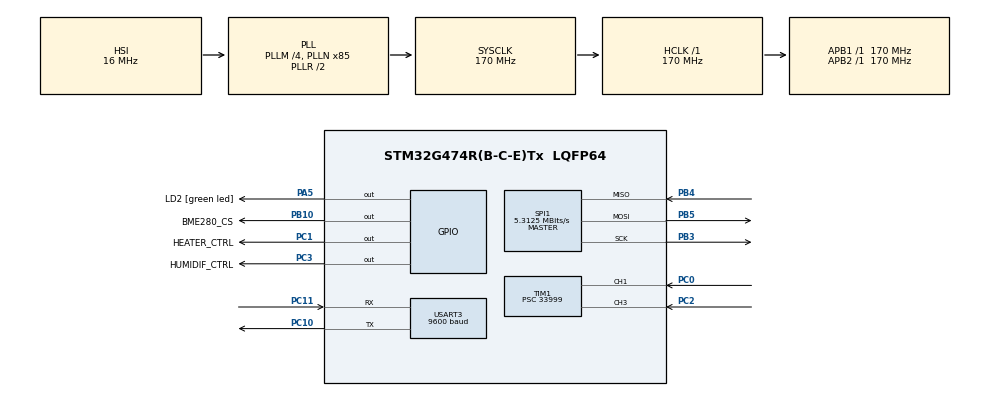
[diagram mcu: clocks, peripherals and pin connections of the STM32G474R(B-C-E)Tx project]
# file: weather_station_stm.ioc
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Mcu.Family=STM32G4
Mcu.Name=STM32G474R(B-C-E)Tx
Mcu.Package=LQFP64
NVIC.PriorityGroup=NVIC_PRIORITYGROUP_4
NVIC.SPI1_IRQn=true\:5\:0\:true\:false\:true\:true\:true\:true
NVIC.TIM1_CC_IRQn=true\:5\:0\:true\:false\:true\:true\:true\:true
NVIC.TIM1_UP_TIM16_IRQn=true\:5\:0\:true\:false\:true\:false\:true\:true
NVIC.TimeBase=TIM1_UP_TIM16_IRQn
NVIC.TimeBaseIP=TIM16
NVIC.USART3_IRQn=true\:5\:0\:true\:false\:true\:true\:true\:true
PA13.GPIO_Label=T_SWDIO
PA13.Mode=Serial_Wire
PA13.Signal=SYS_JTMS-SWDIO
PA14.GPIO_Label=T_SWCLK
PA14.Mode=Serial_Wire
PA14.Signal=SYS_JTCK-SWCLK
PA2.GPIO_Label=LPUART1_TX [STLINKV3E_VCP_RX]
PA2.Signal=LPUART1_TX
PA3.GPIO_Label=LPUART1_RX [STLINKV3E_VCP_TX]
PA3.Signal=LPUART1_RX
PA5.GPIO_Label=LD2 [green led]
PA5.Signal=GPIO_Output
PB10.GPIO_Label=BME280_CS
PB10.Signal=GPIO_Output
PB3.Mode=Full_Duplex_Master
PB3.Signal=SPI1_SCK
PB4.Mode=Full_Duplex_Master
PB4.Signal=SPI1_MISO
PB5.Mode=Full_Duplex_Master
PB5.Signal=SPI1_MOSI
PC0.Signal=S_TIM1_CH1
PC1.GPIO_Label=HEATER_CTRL
PC1.Signal=GPIO_Output
PC10.Mode=Asynchronous
PC10.Signal=USART3_TX
PC11.GPIO_PuPd=GPIO_PULLUP
PC11.Mode=Asynchronous
PC11.Signal=USART3_RX
PC14-OSC32_IN.Mode=LSE-External-Oscillator
PC14-OSC32_IN.Signal=RCC_OSC32_IN
PC15-OSC32_OUT.Mode=LSE-External-Oscillator
PC15-OSC32_OUT.Signal=RCC_OSC32_OUT
PC2.Signal=S_TIM1_CH3
PC3.GPIO_Label=HUMIDIF_CTRL
PC3.Signal=GPIO_Output
PF0-OSC_IN.Mode=HSE-External-Oscillator
PF0-OSC_IN.Signal=RCC_OSC_IN
PF1-OSC_OUT.Mode=HSE-External-Oscillator
PF1-OSC_OUT.Signal=RCC_OSC_OUT
ProjectManager.HeapSize=0x200
ProjectManager.StackSize=0x400
ProjectManager.TargetToolchain=Makefile
RCC.ADC12Freq_Value=170000000
RCC.ADC345Freq_Value=170000000
RCC.AHBFreq_Value=170000000
RCC.APB1Freq_Value=170000000
RCC.APB1TimFreq_Value=170000000
RCC.APB2Freq_Value=170000000
RCC.APB2TimFreq_Value=170000000
RCC.CortexFreq_Value=170000000
RCC.EXTERNAL_CLOCK_VALUE=12288000
RCC.HCLKFreq_Value=170000000
RCC.HSE_VALUE=24000000
RCC.HSI48_VALUE=48000000
RCC.HSI_VALUE=16000000
RCC.PLLM=RCC_PLLM_DIV4
RCC.PLLN=85
RCC.RTCClockSelection=RCC_RTCCLKSOURCE_LSE
RCC.SYSCLKFreq_VALUE=170000000
RCC.SYSCLKSource=RCC_SYSCLKSOURCE_PLLCLK
RCC.USBFreq_Value=170000000
RCC.VCOOutputFreq_Value=340000000
SH.S_TIM1_CH1.0=TIM1_CH1,Input_Capture1_from_TI1
SH.S_TIM1_CH3.0=TIM1_CH3,Input_Capture3_from_TI3
SPI1.BaudRatePrescaler=SPI_BAUDRATEPRESCALER_32
SPI1.CalculateBaudRate=5.3125 MBits/s
SPI1.DataSize=SPI_DATASIZE_8BIT
SPI1.Direction=SPI_DIRECTION_2LINES
SPI1.Mode=SPI_MODE_MASTER
SPI1.VirtualType=VM_MASTER
TIM1.Channel-Input_Capture1_from_TI1=TIM_CHANNEL_1
TIM1.Channel-Input_Capture2_from_TI1_63=TIM_CHANNEL_2
TIM1.Channel-Input_Capture3_from_TI3=TIM_CHANNEL_3
TIM1.Channel-Input_Capture4_from_TI3_63=TIM_CHANNEL_4
TIM1.ClockDivision=TIM_CLOCKDIVISION_DIV4
TIM1.ICFilter_CH1=15
TIM1.ICFilter_CH3=15
TIM1.ICPolarity_CH1=TIM_INPUTCHANNELPOLARITY_FALLING
TIM1.ICPolarity_CH3=TIM_INPUTCHANNELPOLARITY_FALLING
TIM1.Prescaler=33999
USART3.BaudRate=9600
USART3.VirtualMode-Asynchronous=VM_ASYNC
VP_SYS_VS_DBSignals.Mode=DisableDeadBatterySignals
VP_SYS_VS_tim16.Mode=TIM16
VP_TIM1_VS_ClockSourceINT.Mode=Internal
VP_TIM1_VS_indirect_ch1.Mode=Input_Capture2_from_TI1_63
VP_TIM1_VS_indirect_ch3.Mode=Input_Capture4_from_TI3_63
board=NUCLEO-G474RE

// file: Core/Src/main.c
/* USER CODE BEGIN Header */
/**
  ******************************************************************************
  * @file           : main.c
  * @brief          : Main program body
  ******************************************************************************
  * @attention
  *
  * Copyright (c) 2024 STMicroelectronics.
  * All rights reserved.
  *
  * This software is licensed under terms that can be found in the LICENSE file
  * in the root directory of this software component.
  * If no LICENSE file comes with this software, it is provided AS-IS.
  *
  ******************************************************************************
  */
/* USER CODE END Header */
#include "main.h"

/* USER CODE BEGIN Includes */
#include "FreeRTOS.h"
#include "task.h"
/* USER CODE END Includes */

SPI_HandleTypeDef hspi1;

TIM_HandleTypeDef htim1;

UART_HandleTypeDef huart3;

void SystemClock_Config(void);
static void MX_GPIO_Init(void);
static void MX_SPI1_Init(void);
static void MX_TIM1_Init(void);
static void MX_USART3_UART_Init(void);

/* USER CODE BEGIN 0 */
void vStmInit(void) {
  HAL_Init();
  SystemClock_Config();
  MX_GPIO_Init();
  MX_SPI1_Init();
  MX_TIM1_Init();
  MX_USART3_UART_Init();
}
/* USER CODE END 0 */

void SystemClock_Config(void)
{
  RCC_OscInitTypeDef RCC_OscInitStruct = {0};
  RCC_ClkInitTypeDef RCC_ClkInitStruct = {0};

  /** Configure the main internal regulator output voltage
  */
  HAL_PWREx_ControlVoltageScaling(PWR_REGULATOR_VOLTAGE_SCALE1_BOOST);

  /** Initializes the RCC Oscillators according to the specified parameters
  * in the RCC_OscInitTypeDef structure.
  */
  RCC_OscInitStruct.OscillatorType = RCC_OSCILLATORTYPE_HSI;
  RCC_OscInitStruct.HSIState = RCC_HSI_ON;
  RCC_OscInitStruct.HSICalibrationValue = RCC_HSICALIBRATION_DEFAULT;
  RCC_OscInitStruct.PLL.PLLState = RCC_PLL_ON;
  RCC_OscInitStruct.PLL.PLLSource = RCC_PLLSOURCE_HSI;
  RCC_OscInitStruct.PLL.PLLM = RCC_PLLM_DIV4;
  RCC_OscInitStruct.PLL.PLLN = 85;
  RCC_OscInitStruct.PLL.PLLP = RCC_PLLP_DIV2;
  RCC_OscInitStruct.PLL.PLLQ = RCC_PLLQ_DIV2;
  RCC_OscInitStruct.PLL.PLLR = RCC_PLLR_DIV2;
  if (HAL_RCC_OscConfig(&RCC_OscInitStruct) != HAL_OK)
  {
    Error_Handler();
  }

  /** Initializes the CPU, AHB and APB buses clocks
  */
  RCC_ClkInitStruct.ClockType = RCC_CLOCKTYPE_HCLK|RCC_CLOCKTYPE_SYSCLK
                              |RCC_CLOCKTYPE_PCLK1|RCC_CLOCKTYPE_PCLK2;
  RCC_ClkInitStruct.SYSCLKSource = RCC_SYSCLKSOURCE_PLLCLK;
  RCC_ClkInitStruct.AHBCLKDivider = RCC_SYSCLK_DIV1;
  RCC_ClkInitStruct.APB1CLKDivider = RCC_HCLK_DIV1;
  RCC_ClkInitStruct.APB2CLKDivider = RCC_HCLK_DIV1;

  if (HAL_RCC_ClockConfig(&RCC_ClkInitStruct, FLASH_LATENCY_4) != HAL_OK)
  {
    Error_Handler();
  }
}

static void MX_SPI1_Init(void)
{

  /* SPI1 parameter configuration*/
  hspi1.Instance = SPI1;
  hspi1.Init.Mode = SPI_MODE_MASTER;
  hspi1.Init.Direction = SPI_DIRECTION_2LINES;
  hspi1.Init.DataSize = SPI_DATASIZE_8BIT;
  hspi1.Init.CLKPolarity = SPI_POLARITY_LOW;
  hspi1.Init.CLKPhase = SPI_PHASE_1EDGE;
  hspi1.Init.NSS = SPI_NSS_SOFT;
  hspi1.Init.BaudRatePrescaler = SPI_BAUDRATEPRESCALER_32;
  hspi1.Init.FirstBit = SPI_FIRSTBIT_MSB;
  hspi1.Init.TIMode = SPI_TIMODE_DISABLE;
  hspi1.Init.CRCCalculation = SPI_CRCCALCULATION_DISABLE;
  hspi1.Init.CRCPolynomial = 7;
  hspi1.Init.CRCLength = SPI_CRC_LENGTH_DATASIZE;
  hspi1.Init.NSSPMode = SPI_NSS_PULSE_ENABLE;
  if (HAL_SPI_Init(&hspi1) != HAL_OK)
  {
    Error_Handler();
  }

}

static void MX_TIM1_Init(void)
{

  TIM_ClockConfigTypeDef sClockSourceConfig = {0};
  TIM_MasterConfigTypeDef sMasterConfig = {0};
  TIM_IC_InitTypeDef sConfigIC = {0};

  htim1.Instance = TIM1;
  htim1.Init.Prescaler = 33999;
  htim1.Init.CounterMode = TIM_COUNTERMODE_UP;
  htim1.Init.Period = 65535;
  htim1.Init.ClockDivision = TIM_CLOCKDIVISION_DIV4;
  htim1.Init.RepetitionCounter = 0;
  htim1.Init.AutoReloadPreload = TIM_AUTORELOAD_PRELOAD_DISABLE;
  if (HAL_TIM_Base_Init(&htim1) != HAL_OK)
  {
    Error_Handler();
  }
  sClockSourceConfig.ClockSource = TIM_CLOCKSOURCE_INTERNAL;
  if (HAL_TIM_ConfigClockSource(&htim1, &sClockSourceConfig) != HAL_OK)
  {
    Error_Handler();
  }
  if (HAL_TIM_IC_Init(&htim1) != HAL_OK)
  {
    Error_Handler();
  }
  sMasterConfig.MasterOutputTrigger = TIM_TRGO_RESET;
  sMasterConfig.MasterOutputTrigger2 = TIM_TRGO2_RESET;
  sMasterConfig.MasterSlaveMode = TIM_MASTERSLAVEMODE_DISABLE;
  if (HAL_TIMEx_MasterConfigSynchronization(&htim1, &sMasterConfig) != HAL_OK)
  {
    Error_Handler();
  }
  sConfigIC.ICPolarity = TIM_INPUTCHANNELPOLARITY_FALLING;
  sConfigIC.ICSelection = TIM_ICSELECTION_DIRECTTI;
  sConfigIC.ICPrescaler = TIM_ICPSC_DIV1;
  sConfigIC.ICFilter = 15;
  if (HAL_TIM_IC_ConfigChannel(&htim1, &sConfigIC, TIM_CHANNEL_1) != HAL_OK)
  {
    Error_Handler();
  }
  sConfigIC.ICPolarity = TIM_INPUTCHANNELPOLARITY_RISING;
  sConfigIC.ICSelection = TIM_ICSELECTION_INDIRECTTI;
  sConfigIC.ICFilter = 0;
  if (HAL_TIM_IC_ConfigChannel(&htim1, &sConfigIC, TIM_CHANNEL_2) != HAL_OK)
  {
    Error_Handler();
  }
  sConfigIC.ICPolarity = TIM_INPUTCHANNELPOLARITY_FALLING;
  sConfigIC.ICSelection = TIM_ICSELECTION_DIRECTTI;
  sConfigIC.ICFilter = 15;
  if (HAL_TIM_IC_ConfigChannel(&htim1, &sConfigIC, TIM_CHANNEL_3) != HAL_OK)
  {
    Error_Handler();
  }
  sConfigIC.ICPolarity = TIM_INPUTCHANNELPOLARITY_RISING;
  sConfigIC.ICSelection = TIM_ICSELECTION_INDIRECTTI;
  sConfigIC.ICFilter = 0;
  if (HAL_TIM_IC_ConfigChannel(&htim1, &sConfigIC, TIM_CHANNEL_4) != HAL_OK)
  {
    Error_Handler();
  }

}

static void MX_USART3_UART_Init(void)
{

  huart3.Instance = USART3;
  huart3.Init.BaudRate = 9600;
  huart3.Init.WordLength = UART_WORDLENGTH_8B;
  huart3.Init.StopBits = UART_STOPBITS_1;
  huart3.Init.Parity = UART_PARITY_NONE;
  huart3.Init.Mode = UART_MODE_TX_RX;
  huart3.Init.HwFlowCtl = UART_HWCONTROL_NONE;
  huart3.Init.OverSampling = UART_OVERSAMPLING_16;
  huart3.Init.OneBitSampling = UART_ONE_BIT_SAMPLE_DISABLE;
  huart3.Init.ClockPrescaler = UART_PRESCALER_DIV1;
  huart3.AdvancedInit.AdvFeatureInit = UART_ADVFEATURE_NO_INIT;
  if (HAL_UART_Init(&huart3) != HAL_OK)
  {
    Error_Handler();
  }
  if (HAL_UARTEx_SetTxFifoThreshold(&huart3, UART_TXFIFO_THRESHOLD_1_8) != HAL_OK)
  {
    Error_Handler();
  }
  if (HAL_UARTEx_SetRxFifoThreshold(&huart3, UART_RXFIFO_THRESHOLD_1_8) != HAL_OK)
  {
    Error_Handler();
  }
  if (HAL_UARTEx_DisableFifoMode(&huart3) != HAL_OK)
  {
    Error_Handler();
  }

}

static void MX_GPIO_Init(void)
{
  GPIO_InitTypeDef GPIO_InitStruct = {0};

  /* GPIO Ports Clock Enable */
  __HAL_RCC_GPIOC_CLK_ENABLE();
  __HAL_RCC_GPIOF_CLK_ENABLE();
  __HAL_RCC_GPIOA_CLK_ENABLE();
  __HAL_RCC_GPIOB_CLK_ENABLE();

  /*Configure GPIO pin Output Level */
  HAL_GPIO_WritePin(GPIOC, HEATER_CTRL_Pin|HUMIDIF_CTRL_Pin, GPIO_PIN_RESET);

  /*Configure GPIO pin Output Level */
  HAL_GPIO_WritePin(LD2_GPIO_Port, LD2_Pin, GPIO_PIN_RESET);

  /*Configure GPIO pin Output Level */
  HAL_GPIO_WritePin(BME280_CS_GPIO_Port, BME280_CS_Pin, GPIO_PIN_RESET);

  /*Configure GPIO pins : HEATER_CTRL_Pin HUMIDIF_CTRL_Pin */
  GPIO_InitStruct.Pin = HEATER_CTRL_Pin|HUMIDIF_CTRL_Pin;
  GPIO_InitStruct.Mode = GPIO_MODE_OUTPUT_PP;
  GPIO_InitStruct.Pull = GPIO_NOPULL;
  GPIO_InitStruct.Speed = GPIO_SPEED_FREQ_LOW;
  HAL_GPIO_Init(GPIOC, &GPIO_InitStruct);

  /*Configure GPIO pins : LPUART1_TX_Pin LPUART1_RX_Pin */
  GPIO_InitStruct.Pin = LPUART1_TX_Pin|LPUART1_RX_Pin;
  GPIO_InitStruct.Mode = GPIO_MODE_AF_PP;
  GPIO_InitStruct.Pull = GPIO_NOPULL;
  GPIO_InitStruct.Speed = GPIO_SPEED_FREQ_LOW;
  GPIO_InitStruct.Alternate = GPIO_AF12_LPUART1;
  HAL_GPIO_Init(GPIOA, &GPIO_InitStruct);

  /*Configure GPIO pin : LD2_Pin */
  GPIO_InitStruct.Pin = LD2_Pin;
  GPIO_InitStruct.Mode = GPIO_MODE_OUTPUT_PP;
  GPIO_InitStruct.Pull = GPIO_NOPULL;
  GPIO_InitStruct.Speed = GPIO_SPEED_FREQ_LOW;
  HAL_GPIO_Init(LD2_GPIO_Port, &GPIO_InitStruct);

  /*Configure GPIO pin : BME280_CS_Pin */
  GPIO_InitStruct.Pin = BME280_CS_Pin;
  GPIO_InitStruct.Mode = GPIO_MODE_OUTPUT_PP;
  GPIO_InitStruct.Pull = GPIO_NOPULL;
  GPIO_InitStruct.Speed = GPIO_SPEED_FREQ_LOW;
  HAL_GPIO_Init(BME280_CS_GPIO_Port, &GPIO_InitStruct);

}

void HAL_TIM_PeriodElapsedCallback(TIM_HandleTypeDef *htim)
{
  if (htim->Instance == TIM16) {
    HAL_IncTick();
  }
}

void Error_Handler(void)
{
  __disable_irq();
  while (1)
  {
  }
}
